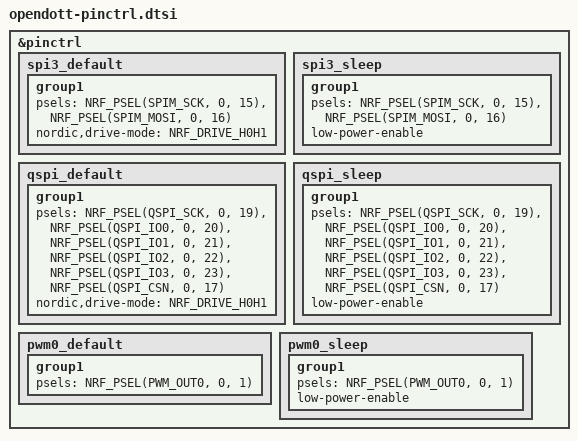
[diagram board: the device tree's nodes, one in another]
/*
 * Pin Control for OpenDOTT
 * 
 * PINS EXTRACTED FROM ORIGINAL FIRMWARE ANALYSIS:
 * - QSPI: Standard nRF52840 pins (CONFIRMED)
 * - SPI Display: P0.15 SCK, P0.16 MOSI (HIGH CONFIDENCE)
 * - PWM Backlight: P0.1 (MEDIUM CONFIDENCE)
 */

&pinctrl {
    /* SPI3 for GC9A01 display - uses SPIM3 (high speed) */
    spi3_default: spi3_default {
        group1 {
            psels = <NRF_PSEL(SPIM_SCK, 0, 15)>,
                    <NRF_PSEL(SPIM_MOSI, 0, 16)>;
            nordic,drive-mode = <NRF_DRIVE_H0H1>;
        };
    };

    spi3_sleep: spi3_sleep {
        group1 {
            psels = <NRF_PSEL(SPIM_SCK, 0, 15)>,
                    <NRF_PSEL(SPIM_MOSI, 0, 16)>;
            low-power-enable;
        };
    };

    /* QSPI for GD25Q128 external flash - CONFIRMED from firmware */
    qspi_default: qspi_default {
        group1 {
            psels = <NRF_PSEL(QSPI_SCK, 0, 19)>,
                    <NRF_PSEL(QSPI_IO0, 0, 20)>,
                    <NRF_PSEL(QSPI_IO1, 0, 21)>,
                    <NRF_PSEL(QSPI_IO2, 0, 22)>,
                    <NRF_PSEL(QSPI_IO3, 0, 23)>,
                    <NRF_PSEL(QSPI_CSN, 0, 17)>;
            nordic,drive-mode = <NRF_DRIVE_H0H1>;
        };
    };

    qspi_sleep: qspi_sleep {
        group1 {
            psels = <NRF_PSEL(QSPI_SCK, 0, 19)>,
                    <NRF_PSEL(QSPI_IO0, 0, 20)>,
                    <NRF_PSEL(QSPI_IO1, 0, 21)>,
                    <NRF_PSEL(QSPI_IO2, 0, 22)>,
                    <NRF_PSEL(QSPI_IO3, 0, 23)>,
                    <NRF_PSEL(QSPI_CSN, 0, 17)>;
            low-power-enable;
        };
    };

    /* PWM for backlight - P0.1 from firmware analysis */
    pwm0_default: pwm0_default {
        group1 {
            psels = <NRF_PSEL(PWM_OUT0, 0, 1)>;
        };
    };

    pwm0_sleep: pwm0_sleep {
        group1 {
            psels = <NRF_PSEL(PWM_OUT0, 0, 1)>;
            low-power-enable;
        };
    };
};
